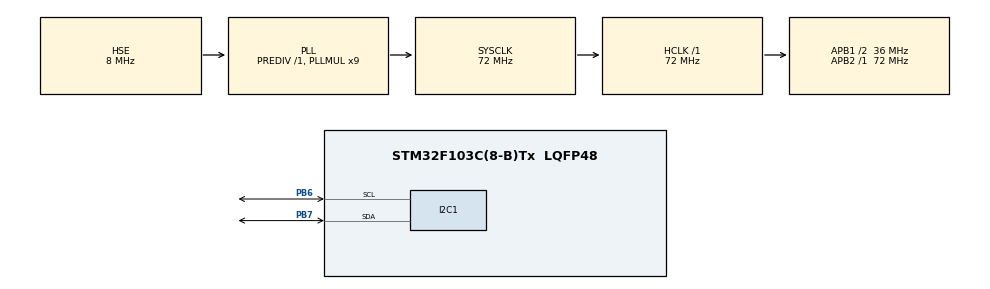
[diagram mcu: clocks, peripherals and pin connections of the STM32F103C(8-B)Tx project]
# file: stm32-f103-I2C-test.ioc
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Dma.I2C1_RX.0.Direction=DMA_PERIPH_TO_MEMORY
Dma.I2C1_RX.0.Instance=DMA1_Channel7
Dma.I2C1_RX.0.MemDataAlignment=DMA_MDATAALIGN_BYTE
Dma.I2C1_RX.0.MemInc=DMA_MINC_ENABLE
Dma.I2C1_RX.0.Mode=DMA_NORMAL
Dma.I2C1_RX.0.PeriphDataAlignment=DMA_PDATAALIGN_BYTE
Dma.I2C1_RX.0.PeriphInc=DMA_PINC_DISABLE
Dma.I2C1_RX.0.Priority=DMA_PRIORITY_MEDIUM
Dma.I2C1_TX.1.Direction=DMA_MEMORY_TO_PERIPH
Dma.I2C1_TX.1.Instance=DMA1_Channel6
Dma.I2C1_TX.1.MemDataAlignment=DMA_MDATAALIGN_BYTE
Dma.I2C1_TX.1.MemInc=DMA_MINC_ENABLE
Dma.I2C1_TX.1.Mode=DMA_NORMAL
Dma.I2C1_TX.1.PeriphDataAlignment=DMA_PDATAALIGN_BYTE
Dma.I2C1_TX.1.PeriphInc=DMA_PINC_DISABLE
Dma.I2C1_TX.1.Priority=DMA_PRIORITY_MEDIUM
Dma.Request0=I2C1_RX
Dma.Request1=I2C1_TX
I2C1.I2C_Mode=I2C_Fast
I2C1.OwnAddress=0
Mcu.Family=STM32F1
Mcu.Name=STM32F103C(8-B)Tx
Mcu.Package=LQFP48
NVIC.DMA1_Channel6_IRQn=true\:1\:0\:true\:false\:true\:false\:true\:true
NVIC.DMA1_Channel7_IRQn=true\:1\:0\:true\:false\:true\:false\:true\:true
NVIC.I2C1_ER_IRQn=true\:0\:0\:false\:false\:true\:true\:true\:true
NVIC.I2C1_EV_IRQn=true\:0\:0\:false\:false\:true\:true\:true\:true
NVIC.PriorityGroup=NVIC_PRIORITYGROUP_4
NVIC.TIM3_IRQn=true\:0\:0\:false\:false\:true\:true\:true\:true
PA13.Mode=Trace_Asynchronous_SW
PA13.Signal=SYS_JTMS-SWDIO
PA14.Mode=Trace_Asynchronous_SW
PA14.Signal=SYS_JTCK-SWCLK
PB3.Mode=Trace_Asynchronous_SW
PB3.Signal=SYS_JTDO-TRACESWO
PB6.Mode=I2C
PB6.Signal=I2C1_SCL
PB7.Mode=I2C
PB7.Signal=I2C1_SDA
PD0-OSC_IN.Mode=HSE-External-Oscillator
PD0-OSC_IN.Signal=RCC_OSC_IN
PD1-OSC_OUT.Mode=HSE-External-Oscillator
PD1-OSC_OUT.Signal=RCC_OSC_OUT
ProjectManager.HeapSize=0x200
ProjectManager.StackSize=0x400
ProjectManager.TargetToolchain=STM32CubeIDE
RCC.AHBFreq_Value=72000000
RCC.APB1CLKDivider=RCC_HCLK_DIV2
RCC.APB1Freq_Value=36000000
RCC.APB1TimFreq_Value=72000000
RCC.APB2Freq_Value=72000000
RCC.APB2TimFreq_Value=72000000
RCC.HCLKFreq_Value=72000000
RCC.PLLMUL=RCC_PLL_MUL9
RCC.PLLSourceVirtual=RCC_PLLSOURCE_HSE
RCC.SYSCLKFreq_VALUE=72000000
RCC.SYSCLKSource=RCC_SYSCLKSOURCE_PLLCLK
RCC.USBFreq_Value=72000000
TIM3.AutoReloadPreload=TIM_AUTORELOAD_PRELOAD_ENABLE
TIM3.Period=999
TIM3.Prescaler=71
VP_TIM3_VS_ClockSourceINT.Mode=Internal
board=custom

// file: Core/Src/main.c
/* USER CODE BEGIN Header */
/**
  ******************************************************************************
  * @file           : main.c
  * @brief          : Main program body
  ******************************************************************************
  * @attention
  *
  * Copyright (c) 2026 STMicroelectronics.
  * All rights reserved.
  *
  * This software is licensed under terms that can be found in the LICENSE file
  * in the root directory of this software component.
  * If no LICENSE file comes with this software, it is provided AS-IS.
  *
  ******************************************************************************
  */
/* USER CODE END Header */
#include "main.h"

/* USER CODE BEGIN Includes */
#include "arm_math.h"
#include "arm_const_structs.h"
/* USER CODE END Includes */

I2C_HandleTypeDef hi2c1;
DMA_HandleTypeDef hdma_i2c1_rx;
DMA_HandleTypeDef hdma_i2c1_tx;

TIM_HandleTypeDef htim3;

/* USER CODE BEGIN PV */
#define FFT_SIZE 256            // FFT 샘플 개수 (2의 거듭제곱)
float32_t fft_output[FFT_SIZE];
uint8_t pData[14];              // MPU6050 데이터를 담을 임시 바구니
float32_t fft_input[FFT_SIZE * 2]; // CMSIS-DSP용 입력 배열 (실수, 허수 쌍)
uint16_t sample_count = 0;      // 현재 수집된 샘플 개수 카운트
uint8_t fft_ready_flag = 0;     // FFT 연산 준비 완료 신호
volatile float32_t maxValue = 0;
volatile uint32_t maxIndex = 0;
volatile float32_t freq = 0;
/* USER CODE END PV */

void SystemClock_Config(void);
static void MX_GPIO_Init(void);
static void MX_DMA_Init(void);
static void MX_I2C1_Init(void);
static void MX_TIM3_Init(void);

/* USER CODE BEGIN 0 */
uint16_t temp_addr = (0x48 << 1);
uint16_t vib_addr = (0x68 << 1);
uint16_t cur_addr = (0x40 << 1);
uint8_t vData[6];
uint8_t tData[2];
uint8_t cData[2];
float temp = 0;
float tempC = 0.0078125;
volatile int16_t x_axis = 0;
volatile int16_t y_axis = 0;
volatile int16_t z_axis = 0;
volatile int8_t flag_dma = 0;
volatile int16_t errorCount = 0;
volatile int16_t temp_t = 0;
volatile int8_t i2c_step = 0;

volatile uint16_t bus_raw = 0;
volatile float bus_voltage = 0;

/* USER CODE END 0 */

int main(void)
{

  /* MCU Configuration--------------------------------------------------------*/

  /* Reset of all peripherals, Initializes the Flash interface and the Systick. */
  HAL_Init();

  /* Configure the system clock */
  SystemClock_Config();

  /* Initialize all configured peripherals */
  MX_GPIO_Init();
  MX_DMA_Init();
  MX_I2C1_Init();
  MX_TIM3_Init();
  /* USER CODE BEGIN 2 */
  HAL_TIM_Base_Start_IT(&htim3);
  /* USER CODE END 2 */

  /* Infinite loop */
  /* USER CODE BEGIN WHILE */
  while (1)
  {
      if (fft_ready_flag == 1)
      {
          // 1. FFT 연산 수행
          arm_cfft_f32(&arm_cfft_sR_f32_len256, fft_input, 0, 1);
          arm_cmplx_mag_f32(fft_input, fft_output, FFT_SIZE);

          // 2. DC 및 저주파 노이즈 제거 (0~15번 인덱스)
          for(int i = 0; i <= 15; i++) fft_output[i] = 0.0f;

          // 3. Peak 찾기
          arm_max_f32(fft_output, FFT_SIZE / 2, (float32_t *)&maxValue, (uint32_t *)&maxIndex);

          // 4. 주파수 계산 및 이동 평균 필터 적용
          if (maxValue > 2.0f) {
              // 이번 회차에서 계산된 실시간 주파수
              float32_t current_freq = (float32_t)maxIndex * 1000.0f / (float32_t)FFT_SIZE;

              // ★ 이동 평균(EMA) 적용: 이전 값(80%) + 현재 값(20%)
              // 숫자가 너무 천천히 변한다면 0.2f를 0.5f 정도로 높이세요.
              freq = (freq * 0.8f) + (current_freq * 0.2f);
          } else {
              // 진동이 없으면 서서히 0으로 수렴하게 하거나 즉시 0으로 만듭니다.
              freq = (freq * 0.5f);
              if(freq < 1.0f) freq = 0.0f;
          }

          // 5. 변수 초기화 및 재시작
          sample_count = 0;
          fft_ready_flag = 0;
      }
  }
  /* USER CODE END 3 */
}

void SystemClock_Config(void)
{
  RCC_OscInitTypeDef RCC_OscInitStruct = {0};
  RCC_ClkInitTypeDef RCC_ClkInitStruct = {0};

  /** Initializes the RCC Oscillators according to the specified parameters
  * in the RCC_OscInitTypeDef structure.
  */
  RCC_OscInitStruct.OscillatorType = RCC_OSCILLATORTYPE_HSE;
  RCC_OscInitStruct.HSEState = RCC_HSE_ON;
  RCC_OscInitStruct.HSEPredivValue = RCC_HSE_PREDIV_DIV1;
  RCC_OscInitStruct.HSIState = RCC_HSI_ON;
  RCC_OscInitStruct.PLL.PLLState = RCC_PLL_ON;
  RCC_OscInitStruct.PLL.PLLSource = RCC_PLLSOURCE_HSE;
  RCC_OscInitStruct.PLL.PLLMUL = RCC_PLL_MUL9;
  if (HAL_RCC_OscConfig(&RCC_OscInitStruct) != HAL_OK)
  {
    Error_Handler();
  }

  /** Initializes the CPU, AHB and APB buses clocks
  */
  RCC_ClkInitStruct.ClockType = RCC_CLOCKTYPE_HCLK|RCC_CLOCKTYPE_SYSCLK
                              |RCC_CLOCKTYPE_PCLK1|RCC_CLOCKTYPE_PCLK2;
  RCC_ClkInitStruct.SYSCLKSource = RCC_SYSCLKSOURCE_PLLCLK;
  RCC_ClkInitStruct.AHBCLKDivider = RCC_SYSCLK_DIV1;
  RCC_ClkInitStruct.APB1CLKDivider = RCC_HCLK_DIV2;
  RCC_ClkInitStruct.APB2CLKDivider = RCC_HCLK_DIV1;

  if (HAL_RCC_ClockConfig(&RCC_ClkInitStruct, FLASH_LATENCY_2) != HAL_OK)
  {
    Error_Handler();
  }
}

static void MX_I2C1_Init(void)
{

  hi2c1.Instance = I2C1;
  hi2c1.Init.ClockSpeed = 400000;
  hi2c1.Init.DutyCycle = I2C_DUTYCYCLE_2;
  hi2c1.Init.OwnAddress1 = 0;
  hi2c1.Init.AddressingMode = I2C_ADDRESSINGMODE_7BIT;
  hi2c1.Init.DualAddressMode = I2C_DUALADDRESS_DISABLE;
  hi2c1.Init.OwnAddress2 = 0;
  hi2c1.Init.GeneralCallMode = I2C_GENERALCALL_DISABLE;
  hi2c1.Init.NoStretchMode = I2C_NOSTRETCH_DISABLE;
  if (HAL_I2C_Init(&hi2c1) != HAL_OK)
  {
    Error_Handler();
  }
  /* USER CODE BEGIN I2C1_Init 2 */
  __HAL_LINKDMA(&hi2c1, hdmarx, hdma_i2c1_rx);
  __HAL_LINKDMA(&hi2c1, hdmatx, hdma_i2c1_tx);
  /* USER CODE END I2C1_Init 2 */

}

static void MX_TIM3_Init(void)
{

  TIM_ClockConfigTypeDef sClockSourceConfig = {0};
  TIM_MasterConfigTypeDef sMasterConfig = {0};

  htim3.Instance = TIM3;
  htim3.Init.Prescaler = 71;
  htim3.Init.CounterMode = TIM_COUNTERMODE_UP;
  htim3.Init.Period = 999;
  htim3.Init.ClockDivision = TIM_CLOCKDIVISION_DIV1;
  htim3.Init.AutoReloadPreload = TIM_AUTORELOAD_PRELOAD_ENABLE;
  if (HAL_TIM_Base_Init(&htim3) != HAL_OK)
  {
    Error_Handler();
  }
  sClockSourceConfig.ClockSource = TIM_CLOCKSOURCE_INTERNAL;
  if (HAL_TIM_ConfigClockSource(&htim3, &sClockSourceConfig) != HAL_OK)
  {
    Error_Handler();
  }
  sMasterConfig.MasterOutputTrigger = TIM_TRGO_RESET;
  sMasterConfig.MasterSlaveMode = TIM_MASTERSLAVEMODE_DISABLE;
  if (HAL_TIMEx_MasterConfigSynchronization(&htim3, &sMasterConfig) != HAL_OK)
  {
    Error_Handler();
  }

}

static void MX_DMA_Init(void)
{

  /* DMA controller clock enable */
  __HAL_RCC_DMA1_CLK_ENABLE();

  /* DMA interrupt init */
  /* DMA1_Channel6_IRQn interrupt configuration */
  HAL_NVIC_SetPriority(DMA1_Channel6_IRQn, 1, 0);
  HAL_NVIC_EnableIRQ(DMA1_Channel6_IRQn);
  /* DMA1_Channel7_IRQn interrupt configuration */
  HAL_NVIC_SetPriority(DMA1_Channel7_IRQn, 1, 0);
  HAL_NVIC_EnableIRQ(DMA1_Channel7_IRQn);

}

static void MX_GPIO_Init(void)
{

  /* GPIO Ports Clock Enable */
  __HAL_RCC_GPIOD_CLK_ENABLE();
  __HAL_RCC_GPIOA_CLK_ENABLE();
  __HAL_RCC_GPIOB_CLK_ENABLE();

}

/* USER CODE BEGIN 4 */
void HAL_I2C_MemRxCpltCallback(I2C_HandleTypeDef *hi2c)
{
    if (hi2c->Instance == I2C1)
    {/* HAL_I2C_MemRxCpltCallback 내부 */
    	int16_t accel_z_raw = (int16_t)(pData[4] << 8 | pData[5]);

    	if (fft_ready_flag == 0) {
    	    // 16384로 나눠서 1.0g 단위로 정규화합니다. 연산이 훨씬 정확해집니다.
    	    fft_input[sample_count * 2] = (float32_t)accel_z_raw / 16384.0f;
    	    fft_input[sample_count * 2 + 1] = 0.0f;
    	    sample_count++;

    	    if (sample_count >= FFT_SIZE) {
    	        fft_ready_flag = 1;
    	    }
    	}
    }
}
void HAL_I2C_ErrorCallback(I2C_HandleTypeDef *hi2c) {
    if (hi2c->Instance == I2C1) {

        // 1. I2C 주변장치 리셋
        __HAL_I2C_DISABLE(hi2c);
        HAL_Delay(1);
        __HAL_I2C_ENABLE(hi2c);

        // 2. 재설정 및 통신 재시작
        HAL_I2C_Init(hi2c);
        i2c_step = 0;
        HAL_I2C_Mem_Read_DMA(&hi2c1, vib_addr, 0x3B, 1, vData, 6);
    }
}

void HAL_TIM_PeriodElapsedCallback(TIM_HandleTypeDef *htim)
{
    if (htim->Instance == TIM3) {
        // 1ms마다 실행될 코드
        // 여기서 MPU6050 데이터를 DMA로 읽어오라고 시킵니다.
        HAL_I2C_Mem_Read_DMA(&hi2c1, (vib_addr), 0x3B, 1, pData, 14);
    }
}

/* USER CODE END 4 */

void Error_Handler(void)
{
  __disable_irq();
  while (1)
  {
  }
}
